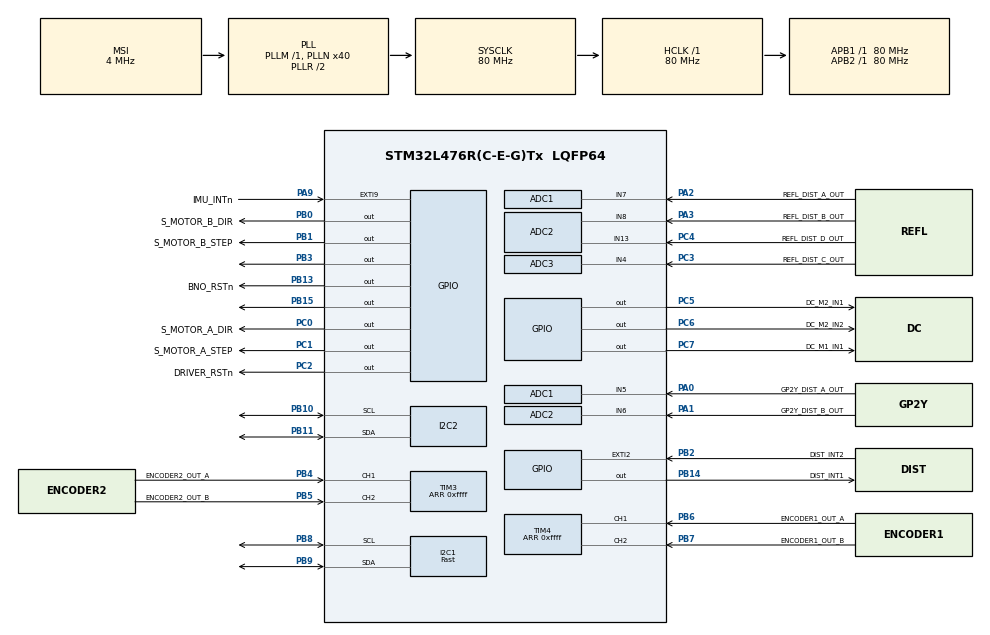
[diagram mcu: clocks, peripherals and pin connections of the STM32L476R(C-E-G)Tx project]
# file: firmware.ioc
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ADC1.Channel-0\#ChannelRegularConversion=ADC_CHANNEL_5
ADC1.Channel-1\#ChannelRegularConversion=ADC_CHANNEL_7
ADC1.ClockPrescaler=ADC_CLOCK_ASYNC_DIV2
ADC1.ContinuousConvMode=ENABLE
ADC1.DMAContinuousRequests=ENABLE
ADC1.DataAlign=ADC_DATAALIGN_RIGHT
ADC1.DiscontinuousConvMode=DISABLE
ADC1.EOCSelection=ADC_EOC_SINGLE_CONV
ADC1.EnableAnalogWatchDog1=false
ADC1.EnableAnalogWatchDog2=false
ADC1.EnableAnalogWatchDog3=false
ADC1.EnableInjectedConversion=DISABLE
ADC1.EnableRegularConversion=ENABLE
ADC1.ExternalTrigConv=ADC_SOFTWARE_START
ADC1.ExternalTrigConvEdge=ADC_EXTERNALTRIGCONVEDGE_NONE
ADC1.LowPowerAutoWait=DISABLE
ADC1.NbrOfConversion=2
ADC1.NbrOfConversionFlag=1
ADC1.OffsetNumber-0\#ChannelRegularConversion=ADC_OFFSET_NONE
ADC1.OffsetNumber-1\#ChannelRegularConversion=ADC_OFFSET_NONE
ADC1.Overrun=ADC_OVR_DATA_OVERWRITTEN
ADC1.OversamplingMode=ENABLE
ADC1.OversamplingStopReset=ADC_REGOVERSAMPLING_CONTINUED_MODE
ADC1.Rank-0\#ChannelRegularConversion=1
ADC1.Rank-1\#ChannelRegularConversion=2
ADC1.Ratio=ADC_OVERSAMPLING_RATIO_256
ADC1.Resolution=ADC_RESOLUTION_12B
ADC1.RightBitShift=ADC_RIGHTBITSHIFT_8
ADC1.SamplingTime-0\#ChannelRegularConversion=ADC_SAMPLETIME_640CYCLES_5
ADC1.SamplingTime-1\#ChannelRegularConversion=ADC_SAMPLETIME_640CYCLES_5
ADC1.ScanConvMode=ADC_SCAN_ENABLE
ADC1.TriggeredMode=ADC_TRIGGEREDMODE_SINGLE_TRIGGER
ADC1.master=1
ADC2.Channel-0\#ChannelRegularConversion=ADC_CHANNEL_6
ADC2.ClockPrescaler=ADC_CLOCK_ASYNC_DIV2
ADC2.ContinuousConvMode=ENABLE
ADC2.DMAContinuousRequests=ENABLE
ADC2.NbrOfConversionFlag=1
ADC2.OffsetNumber-0\#ChannelRegularConversion=ADC_OFFSET_NONE
ADC2.Overrun=ADC_OVR_DATA_OVERWRITTEN
ADC2.OversamplingMode=ENABLE
ADC2.Rank-0\#ChannelRegularConversion=1
ADC2.Ratio=ADC_OVERSAMPLING_RATIO_256
ADC2.RightBitShift=ADC_RIGHTBITSHIFT_8
ADC2.SamplingTime-0\#ChannelRegularConversion=ADC_SAMPLETIME_2CYCLES_5
ADC3.Channel-0\#ChannelRegularConversion=ADC_CHANNEL_4
ADC3.ClockPrescaler=ADC_CLOCK_ASYNC_DIV2
ADC3.ContinuousConvMode=ENABLE
ADC3.DMAContinuousRequests=ENABLE
ADC3.NbrOfConversionFlag=1
ADC3.OffsetNumber-0\#ChannelRegularConversion=ADC_OFFSET_NONE
ADC3.Overrun=ADC_OVR_DATA_OVERWRITTEN
ADC3.OversamplingMode=ENABLE
ADC3.Rank-0\#ChannelRegularConversion=1
ADC3.Ratio=ADC_OVERSAMPLING_RATIO_256
ADC3.RightBitShift=ADC_RIGHTBITSHIFT_8
ADC3.SamplingTime-0\#ChannelRegularConversion=ADC_SAMPLETIME_2CYCLES_5
Dma.ADC1.2.Direction=DMA_PERIPH_TO_MEMORY
Dma.ADC1.2.Instance=DMA1_Channel1
Dma.ADC1.2.MemDataAlignment=DMA_MDATAALIGN_HALFWORD
Dma.ADC1.2.MemInc=DMA_MINC_ENABLE
Dma.ADC1.2.Mode=DMA_CIRCULAR
Dma.ADC1.2.PeriphDataAlignment=DMA_PDATAALIGN_HALFWORD
Dma.ADC1.2.PeriphInc=DMA_PINC_DISABLE
Dma.ADC1.2.Priority=DMA_PRIORITY_LOW
Dma.ADC2.0.Direction=DMA_PERIPH_TO_MEMORY
Dma.ADC2.0.Instance=DMA1_Channel2
Dma.ADC2.0.MemDataAlignment=DMA_MDATAALIGN_HALFWORD
Dma.ADC2.0.MemInc=DMA_MINC_ENABLE
Dma.ADC2.0.Mode=DMA_CIRCULAR
Dma.ADC2.0.PeriphDataAlignment=DMA_PDATAALIGN_HALFWORD
Dma.ADC2.0.PeriphInc=DMA_PINC_DISABLE
Dma.ADC2.0.Priority=DMA_PRIORITY_LOW
Dma.ADC3.1.Direction=DMA_PERIPH_TO_MEMORY
Dma.ADC3.1.Instance=DMA2_Channel5
Dma.ADC3.1.MemDataAlignment=DMA_MDATAALIGN_HALFWORD
Dma.ADC3.1.MemInc=DMA_MINC_ENABLE
Dma.ADC3.1.Mode=DMA_CIRCULAR
Dma.ADC3.1.PeriphDataAlignment=DMA_PDATAALIGN_HALFWORD
Dma.ADC3.1.PeriphInc=DMA_PINC_DISABLE
Dma.ADC3.1.Priority=DMA_PRIORITY_LOW
Dma.Request0=ADC2
Dma.Request1=ADC3
Dma.Request2=ADC1
I2C1.I2C_Fall_Time=200
I2C1.I2C_Rise_Time=200
I2C1.I2C_Speed_Mode=I2C_Fast
I2C1.Speed=400
I2C1.Timing=0x10B51438
I2C2.Timing=0x10909CEC
Mcu.Family=STM32L4
Mcu.Name=STM32L476R(C-E-G)Tx
Mcu.Package=LQFP64
NVIC.DMA1_Channel1_IRQn=true\:0\:0\:false\:false\:true
NVIC.DMA1_Channel2_IRQn=true\:0\:0\:false\:false\:true
NVIC.DMA2_Channel5_IRQn=true\:0\:0\:false\:false\:true
NVIC.PriorityGroup=NVIC_PRIORITYGROUP_4
NVIC.TIM1_UP_TIM16_IRQn=true\:0\:0\:false\:true\:true\:1
NVIC.TIM2_IRQn=true\:0\:0\:false\:true\:true\:2
PA0.GPIO_Label=GP2Y_DIST_A_OUT
PA0.Signal=ADCx_IN5
PA1.GPIO_Label=GP2Y_DIST_B_OUT
PA1.Signal=ADCx_IN6
PA13.GPIO_Label=SWDIO
PA13.Mode=Serial_Wire
PA13.Signal=SYS_JTMS-SWDIO
PA14.GPIO_Label=SWCLK
PA14.Mode=Serial_Wire
PA14.Signal=SYS_JTCK-SWCLK
PA2.GPIO_Label=REFL_DIST_A_OUT
PA2.Signal=ADCx_IN7
PA3.GPIO_Label=REFL_DIST_B_OUT
PA3.Signal=ADCx_IN8
PA9.GPIO_Label=IMU_INTn
PA9.Signal=GPXTI9
PB0.GPIO_Label=S_MOTOR_B_DIR
PB0.Signal=GPIO_Output
PB1.GPIO_Label=S_MOTOR_B_STEP
PB1.Signal=GPIO_Output
PB10.Mode=I2C
PB10.Signal=I2C2_SCL
PB11.Mode=I2C
PB11.Signal=I2C2_SDA
PB13.GPIO_Label=BNO_RSTn
PB13.Signal=GPIO_Output
PB14.GPIO_Label=DIST_INT1
PB14.Signal=GPIO_Output
PB15.Signal=GPIO_Output
PB2.GPIO_Label=DIST_INT2
PB2.Signal=GPXTI2
PB3.Signal=GPIO_Output
PB4.GPIO_Label=ENCODER2_OUT_A
PB4.Signal=S_TIM3_CH1
PB5.GPIO_Label=ENCODER2_OUT_B
PB5.Signal=S_TIM3_CH2
PB6.GPIO_Label=ENCODER1_OUT_A
PB6.Signal=S_TIM4_CH1
PB7.GPIO_Label=ENCODER1_OUT_B
PB7.Signal=S_TIM4_CH2
PB8.Mode=I2C
PB8.Signal=I2C1_SCL
PB9.Mode=I2C
PB9.Signal=I2C1_SDA
PC0.GPIO_Label=S_MOTOR_A_DIR
PC0.Signal=GPIO_Output
PC1.GPIO_Label=S_MOTOR_A_STEP
PC1.Signal=GPIO_Output
PC14/OSC32_IN.GPIO_Label=OSC32_IN
PC14/OSC32_IN.Mode=LSE-External-Oscillator
PC14/OSC32_IN.Signal=RCC_OSC32_IN
PC15/OSC32_OUT.GPIO_Label=OSC32_OUT
PC15/OSC32_OUT.Mode=LSE-External-Oscillator
PC15/OSC32_OUT.Signal=RCC_OSC32_OUT
PC2.GPIO_Label=DRIVER_RSTn
PC2.Signal=GPIO_Output
PC3.GPIO_Label=REFL_DIST_C_OUT
PC3.Signal=ADCx_IN4
PC4.GPIO_Label=REFL_DIST_D_OUT
PC4.Signal=ADCx_IN13
PC5.GPIO_Label=DC_M2_IN1
PC5.Signal=GPIO_Output
PC6.GPIO_Label=DC_M2_IN2
PC6.Signal=GPIO_Output
PC7.GPIO_Label=DC_M1_IN1
PC7.Signal=GPIO_Output
ProjectManager.HeapSize=0x200
ProjectManager.StackSize=0x400
ProjectManager.TargetToolchain=Other Toolchains (GPDSC)
RCC.ADCCLockSelection=RCC_ADCCLKSOURCE_SYSCLK
RCC.ADCFreq_Value=80000000
RCC.AHBFreq_Value=80000000
RCC.APB1Freq_Value=80000000
RCC.APB1TimFreq_Value=80000000
RCC.APB2Freq_Value=80000000
RCC.APB2TimFreq_Value=80000000
RCC.CortexFreq_Value=80000000
RCC.HCLKFreq_Value=80000000
RCC.HSE_VALUE=8000000
RCC.HSI_VALUE=16000000
RCC.MSI_VALUE=4000000
RCC.PLLN=10
RCC.PLLQ=RCC_PLLQ_DIV4
RCC.PLLSAI1R=RCC_PLLR_DIV4
RCC.PLLSourceVirtual=RCC_PLLSOURCE_HSI
RCC.PWR_Regulator_Voltage_Scale=PWR_REGULATOR_VOLTAGE_SCALE1
RCC.SYSCLKFreq_VALUE=80000000
RCC.SYSCLKSource=RCC_SYSCLKSOURCE_PLLCLK
RCC.USBFreq_Value=64000000
RCC.VCOOutputFreq_Value=160000000
SH.ADCx_IN13.0=ADC2_IN13,IN13-Single-Ended
SH.ADCx_IN4.0=ADC3_IN4,IN4-Single-Ended
SH.ADCx_IN5.0=ADC1_IN5,IN5-Single-Ended
SH.ADCx_IN6.0=ADC2_IN6,IN6-Single-Ended
SH.ADCx_IN7.0=ADC1_IN7,IN7-Single-Ended
SH.ADCx_IN8.0=ADC2_IN8,IN8-Single-Ended
SH.S_TIM3_CH1.0=TIM3_CH1,Encoder_Interface
SH.S_TIM3_CH2.0=TIM3_CH2,Encoder_Interface
SH.S_TIM4_CH1.0=TIM4_CH1,Encoder_Interface
SH.S_TIM4_CH2.0=TIM4_CH2,Encoder_Interface
TIM1.Period=0
TIM1.Prescaler=1
TIM3.EncoderMode=TIM_ENCODERMODE_TI12
TIM3.Period=0xffff
TIM4.EncoderMode=TIM_ENCODERMODE_TI12
TIM4.Period=0xffff
VP_TIM1_VS_ClockSourceINT.Mode=Internal
VP_TIM2_VS_ClockSourceINT.Mode=Internal
board=firmware

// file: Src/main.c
/**
  ******************************************************************************
  * File Name          : main.c
  * Description        : Main program body
  ******************************************************************************
  *
  * COPYRIGHT(c) 2017 STMicroelectronics
  *
  * Redistribution and use in source and binary forms, with or without modification,
  * are permitted provided that the following conditions are met:
  *   1. Redistributions of source code must retain the above copyright notice,
  *      this list of conditions and the following disclaimer.
  *   2. Redistributions in binary form must reproduce the above copyright notice,
  *      this list of conditions and the following disclaimer in the documentation
  *      and/or other materials provided with the distribution.
  *   3. Neither the name of STMicroelectronics nor the names of its contributors
  *      may be used to endorse or promote products derived from this software
  *      without specific prior written permission.
  *
  * THIS SOFTWARE IS PROVIDED BY THE COPYRIGHT HOLDERS AND CONTRIBUTORS "AS IS"
  * AND ANY EXPRESS OR IMPLIED WARRANTIES, INCLUDING, BUT NOT LIMITED TO, THE
  * IMPLIED WARRANTIES OF MERCHANTABILITY AND FITNESS FOR A PARTICULAR PURPOSE ARE
  * DISCLAIMED. IN NO EVENT SHALL THE COPYRIGHT HOLDER OR CONTRIBUTORS BE LIABLE
  * FOR ANY DIRECT, INDIRECT, INCIDENTAL, SPECIAL, EXEMPLARY, OR CONSEQUENTIAL
  * DAMAGES (INCLUDING, BUT NOT LIMITED TO, PROCUREMENT OF SUBSTITUTE GOODS OR
  * SERVICES; LOSS OF USE, DATA, OR PROFITS; OR BUSINESS INTERRUPTION) HOWEVER
  * CAUSED AND ON ANY THEORY OF LIABILITY, WHETHER IN CONTRACT, STRICT LIABILITY,
  * OR TORT (INCLUDING NEGLIGENCE OR OTHERWISE) ARISING IN ANY WAY OUT OF THE USE
  * OF THIS SOFTWARE, EVEN IF ADVISED OF THE POSSIBILITY OF SUCH DAMAGE.
  *
  ******************************************************************************
  */
#include "main.h"

/* USER CODE BEGIN Includes */
#ifdef __cplusplus
extern "C"
#endif
/* USER CODE END Includes */

ADC_HandleTypeDef hadc1;
ADC_HandleTypeDef hadc2;
ADC_HandleTypeDef hadc3;
DMA_HandleTypeDef hdma_adc1;
DMA_HandleTypeDef hdma_adc2;
DMA_HandleTypeDef hdma_adc3;

I2C_HandleTypeDef hi2c1;
I2C_HandleTypeDef hi2c2;

TIM_HandleTypeDef htim1;
TIM_HandleTypeDef htim2;
TIM_HandleTypeDef htim3;
TIM_HandleTypeDef htim4;

/* USER CODE BEGIN PV */
/* Private variables ---------------------------------------------------------*/

/* USER CODE END PV */

void SystemClock_Config(void);
void Error_Handler(void);
static void MX_GPIO_Init(void);
static void MX_DMA_Init(void);
static void MX_ADC1_Init(void);
static void MX_ADC2_Init(void);
static void MX_ADC3_Init(void);
static void MX_I2C1_Init(void);
static void MX_I2C2_Init(void);
static void MX_TIM3_Init(void);
static void MX_TIM4_Init(void);
static void MX_TIM1_Init(void);
static void MX_TIM2_Init(void);
static void MX_NVIC_Init(void);

/* USER CODE BEGIN PFP */
/* Private function prototypes -----------------------------------------------*/

/* USER CODE END PFP */

int CMain(void)
{

  /* MCU Configuration----------------------------------------------------------*/

  /* Reset of all peripherals, Initializes the Flash interface and the Systick. */
  HAL_Init();

  /* Configure the system clock */
  SystemClock_Config();

  /* Initialize all configured peripherals */
  MX_GPIO_Init();
  MX_DMA_Init();
  MX_ADC1_Init();
  MX_ADC2_Init();
  MX_ADC3_Init();
  MX_I2C1_Init();
  MX_I2C2_Init();
  MX_TIM3_Init();
  MX_TIM4_Init();
  MX_TIM1_Init();
  MX_TIM2_Init();

  /* Initialize interrupts */
  MX_NVIC_Init();

  /* USER CODE BEGIN 2 */
    HAL_NVIC_SetPriority(TIM1_UP_TIM16_IRQn, 0, 0);
    HAL_NVIC_EnableIRQ(TIM1_UP_TIM16_IRQn);
  /* USER CODE END 2 */

  /* Infinite loop */

  /* USER CODE BEGIN 3 */
    return 0;
  /* USER CODE END 3 */

}

/** System Clock Configuration
*/
void SystemClock_Config(void)
{

  RCC_OscInitTypeDef RCC_OscInitStruct;
  RCC_ClkInitTypeDef RCC_ClkInitStruct;
  RCC_PeriphCLKInitTypeDef PeriphClkInit;

    /**Initializes the CPU, AHB and APB busses clocks
    */
  RCC_OscInitStruct.OscillatorType = RCC_OSCILLATORTYPE_LSE|RCC_OSCILLATORTYPE_MSI;
  RCC_OscInitStruct.LSEState = RCC_LSE_ON;
  RCC_OscInitStruct.MSIState = RCC_MSI_ON;
  RCC_OscInitStruct.MSICalibrationValue = 0;
  RCC_OscInitStruct.MSIClockRange = RCC_MSIRANGE_6;
  RCC_OscInitStruct.PLL.PLLState = RCC_PLL_ON;
  RCC_OscInitStruct.PLL.PLLSource = RCC_PLLSOURCE_MSI;
  RCC_OscInitStruct.PLL.PLLM = 1;
  RCC_OscInitStruct.PLL.PLLN = 40;
  RCC_OscInitStruct.PLL.PLLP = RCC_PLLP_DIV7;
  RCC_OscInitStruct.PLL.PLLQ = RCC_PLLQ_DIV4;
  RCC_OscInitStruct.PLL.PLLR = RCC_PLLR_DIV2;
  if (HAL_RCC_OscConfig(&RCC_OscInitStruct) != HAL_OK)
  {
    Error_Handler();
  }

    /**Initializes the CPU, AHB and APB busses clocks
    */
  RCC_ClkInitStruct.ClockType = RCC_CLOCKTYPE_HCLK|RCC_CLOCKTYPE_SYSCLK
                              |RCC_CLOCKTYPE_PCLK1|RCC_CLOCKTYPE_PCLK2;
  RCC_ClkInitStruct.SYSCLKSource = RCC_SYSCLKSOURCE_PLLCLK;
  RCC_ClkInitStruct.AHBCLKDivider = RCC_SYSCLK_DIV1;
  RCC_ClkInitStruct.APB1CLKDivider = RCC_HCLK_DIV1;
  RCC_ClkInitStruct.APB2CLKDivider = RCC_HCLK_DIV1;

  if (HAL_RCC_ClockConfig(&RCC_ClkInitStruct, FLASH_LATENCY_4) != HAL_OK)
  {
    Error_Handler();
  }

  PeriphClkInit.PeriphClockSelection = RCC_PERIPHCLK_I2C1|RCC_PERIPHCLK_I2C2
                              |RCC_PERIPHCLK_ADC;
  PeriphClkInit.I2c1ClockSelection = RCC_I2C1CLKSOURCE_PCLK1;
  PeriphClkInit.I2c2ClockSelection = RCC_I2C2CLKSOURCE_PCLK1;
  PeriphClkInit.AdcClockSelection = RCC_ADCCLKSOURCE_PLLSAI1;
  PeriphClkInit.PLLSAI1.PLLSAI1Source = RCC_PLLSOURCE_MSI;
  PeriphClkInit.PLLSAI1.PLLSAI1M = 1;
  PeriphClkInit.PLLSAI1.PLLSAI1N = 16;
  PeriphClkInit.PLLSAI1.PLLSAI1P = RCC_PLLP_DIV7;
  PeriphClkInit.PLLSAI1.PLLSAI1Q = RCC_PLLQ_DIV2;
  PeriphClkInit.PLLSAI1.PLLSAI1R = RCC_PLLR_DIV2;
  PeriphClkInit.PLLSAI1.PLLSAI1ClockOut = RCC_PLLSAI1_ADC1CLK;
  if (HAL_RCCEx_PeriphCLKConfig(&PeriphClkInit) != HAL_OK)
  {
    Error_Handler();
  }

    /**Configure LSE Drive Capability
    */
  __HAL_RCC_LSEDRIVE_CONFIG(RCC_LSEDRIVE_LOW);

    /**Configure the main internal regulator output voltage
    */
  if (HAL_PWREx_ControlVoltageScaling(PWR_REGULATOR_VOLTAGE_SCALE1) != HAL_OK)
  {
    Error_Handler();
  }

    /**Configure the Systick interrupt time
    */
  HAL_SYSTICK_Config(HAL_RCC_GetHCLKFreq()/1000);

    /**Configure the Systick
    */
  HAL_SYSTICK_CLKSourceConfig(SYSTICK_CLKSOURCE_HCLK);

    /**Enable MSI Auto calibration
    */
  HAL_RCCEx_EnableMSIPLLMode();

  /* SysTick_IRQn interrupt configuration */
  HAL_NVIC_SetPriority(SysTick_IRQn, 0, 0);
}

/** NVIC Configuration
*/
static void MX_NVIC_Init(void)
{
  /* TIM1_UP_TIM16_IRQn interrupt configuration */
  HAL_NVIC_SetPriority(TIM1_UP_TIM16_IRQn, 0, 0);
  HAL_NVIC_EnableIRQ(TIM1_UP_TIM16_IRQn);
  /* TIM2_IRQn interrupt configuration */
  HAL_NVIC_SetPriority(TIM2_IRQn, 0, 0);
  HAL_NVIC_EnableIRQ(TIM2_IRQn);
}

/* ADC1 init function */
static void MX_ADC1_Init(void)
{

  ADC_MultiModeTypeDef multimode;
  ADC_ChannelConfTypeDef sConfig;

    /**Common config
    */
  hadc1.Instance = ADC1;
  hadc1.Init.ClockPrescaler = ADC_CLOCK_ASYNC_DIV1;
  hadc1.Init.Resolution = ADC_RESOLUTION_12B;
  hadc1.Init.DataAlign = ADC_DATAALIGN_RIGHT;
  hadc1.Init.ScanConvMode = ADC_SCAN_DISABLE;
  hadc1.Init.EOCSelection = ADC_EOC_SINGLE_CONV;
  hadc1.Init.LowPowerAutoWait = DISABLE;
  hadc1.Init.ContinuousConvMode = ENABLE;
  hadc1.Init.NbrOfConversion = 1;
  hadc1.Init.DiscontinuousConvMode = DISABLE;
  hadc1.Init.NbrOfDiscConversion = 1;
  hadc1.Init.ExternalTrigConv = ADC_SOFTWARE_START;
  hadc1.Init.ExternalTrigConvEdge = ADC_EXTERNALTRIGCONVEDGE_NONE;
  hadc1.Init.DMAContinuousRequests = ENABLE;
  hadc1.Init.Overrun = ADC_OVR_DATA_OVERWRITTEN;
  hadc1.Init.OversamplingMode = ENABLE;
  hadc1.Init.Oversampling.Ratio = ADC_OVERSAMPLING_RATIO_256;
  hadc1.Init.Oversampling.RightBitShift = ADC_RIGHTBITSHIFT_8;
  hadc1.Init.Oversampling.TriggeredMode = ADC_TRIGGEREDMODE_SINGLE_TRIGGER;
  hadc1.Init.Oversampling.OversamplingStopReset = ADC_REGOVERSAMPLING_CONTINUED_MODE;
  if (HAL_ADC_Init(&hadc1) != HAL_OK)
  {
    Error_Handler();
  }

    /**Configure the ADC multi-mode
    */
  multimode.Mode = ADC_MODE_INDEPENDENT;
  if (HAL_ADCEx_MultiModeConfigChannel(&hadc1, &multimode) != HAL_OK)
  {
    Error_Handler();
  }

    /**Configure Regular Channel
    */
  sConfig.Channel = ADC_CHANNEL_5;
  sConfig.Rank = 1;
  sConfig.SamplingTime = ADC_SAMPLETIME_2CYCLES_5;
  sConfig.SingleDiff = ADC_SINGLE_ENDED;
  sConfig.OffsetNumber = ADC_OFFSET_NONE;
  sConfig.Offset = 0;
  if (HAL_ADC_ConfigChannel(&hadc1, &sConfig) != HAL_OK)
  {
    Error_Handler();
  }

}

/* ADC2 init function */
static void MX_ADC2_Init(void)
{

  ADC_ChannelConfTypeDef sConfig;

    /**Common config
    */
  hadc2.Instance = ADC2;
  hadc2.Init.ClockPrescaler = ADC_CLOCK_ASYNC_DIV1;
  hadc2.Init.Resolution = ADC_RESOLUTION_12B;
  hadc2.Init.DataAlign = ADC_DATAALIGN_RIGHT;
  hadc2.Init.ScanConvMode = ADC_SCAN_DISABLE;
  hadc2.Init.EOCSelection = ADC_EOC_SINGLE_CONV;
  hadc2.Init.LowPowerAutoWait = DISABLE;
  hadc2.Init.ContinuousConvMode = ENABLE;
  hadc2.Init.NbrOfConversion = 1;
  hadc2.Init.DiscontinuousConvMode = DISABLE;
  hadc2.Init.NbrOfDiscConversion = 1;
  hadc2.Init.ExternalTrigConv = ADC_SOFTWARE_START;
  hadc2.Init.ExternalTrigConvEdge = ADC_EXTERNALTRIGCONVEDGE_NONE;
  hadc2.Init.DMAContinuousRequests = ENABLE;
  hadc2.Init.Overrun = ADC_OVR_DATA_OVERWRITTEN;
  hadc2.Init.OversamplingMode = ENABLE;
  hadc2.Init.Oversampling.Ratio = ADC_OVERSAMPLING_RATIO_256;
  hadc2.Init.Oversampling.RightBitShift = ADC_RIGHTBITSHIFT_8;
  hadc2.Init.Oversampling.TriggeredMode = ADC_TRIGGEREDMODE_SINGLE_TRIGGER;
  hadc2.Init.Oversampling.OversamplingStopReset = ADC_REGOVERSAMPLING_CONTINUED_MODE;
  if (HAL_ADC_Init(&hadc2) != HAL_OK)
  {
    Error_Handler();
  }

    /**Configure Regular Channel
    */
  sConfig.Channel = ADC_CHANNEL_6;
  sConfig.Rank = 1;
  sConfig.SamplingTime = ADC_SAMPLETIME_2CYCLES_5;
  sConfig.SingleDiff = ADC_SINGLE_ENDED;
  sConfig.OffsetNumber = ADC_OFFSET_NONE;
  sConfig.Offset = 0;
  if (HAL_ADC_ConfigChannel(&hadc2, &sConfig) != HAL_OK)
  {
    Error_Handler();
  }

}

/* ADC3 init function */
static void MX_ADC3_Init(void)
{

  ADC_ChannelConfTypeDef sConfig;

    /**Common config
    */
  hadc3.Instance = ADC3;
  hadc3.Init.ClockPrescaler = ADC_CLOCK_ASYNC_DIV1;
  hadc3.Init.Resolution = ADC_RESOLUTION_12B;
  hadc3.Init.DataAlign = ADC_DATAALIGN_RIGHT;
  hadc3.Init.ScanConvMode = ADC_SCAN_DISABLE;
  hadc3.Init.EOCSelection = ADC_EOC_SINGLE_CONV;
  hadc3.Init.LowPowerAutoWait = DISABLE;
  hadc3.Init.ContinuousConvMode = ENABLE;
  hadc3.Init.NbrOfConversion = 1;
  hadc3.Init.DiscontinuousConvMode = DISABLE;
  hadc3.Init.NbrOfDiscConversion = 1;
  hadc3.Init.ExternalTrigConv = ADC_SOFTWARE_START;
  hadc3.Init.ExternalTrigConvEdge = ADC_EXTERNALTRIGCONVEDGE_NONE;
  hadc3.Init.DMAContinuousRequests = ENABLE;
  hadc3.Init.Overrun = ADC_OVR_DATA_OVERWRITTEN;
  hadc3.Init.OversamplingMode = ENABLE;
  hadc3.Init.Oversampling.Ratio = ADC_OVERSAMPLING_RATIO_256;
  hadc3.Init.Oversampling.RightBitShift = ADC_RIGHTBITSHIFT_8;
  hadc3.Init.Oversampling.TriggeredMode = ADC_TRIGGEREDMODE_SINGLE_TRIGGER;
  hadc3.Init.Oversampling.OversamplingStopReset = ADC_REGOVERSAMPLING_CONTINUED_MODE;
  if (HAL_ADC_Init(&hadc3) != HAL_OK)
  {
    Error_Handler();
  }

    /**Configure Regular Channel
    */
  sConfig.Channel = ADC_CHANNEL_4;
  sConfig.Rank = 1;
  sConfig.SamplingTime = ADC_SAMPLETIME_2CYCLES_5;
  sConfig.SingleDiff = ADC_SINGLE_ENDED;
  sConfig.OffsetNumber = ADC_OFFSET_NONE;
  sConfig.Offset = 0;
  if (HAL_ADC_ConfigChannel(&hadc3, &sConfig) != HAL_OK)
  {
    Error_Handler();
  }

}

/* I2C1 init function */
static void MX_I2C1_Init(void)
{

  hi2c1.Instance = I2C1;
  hi2c1.Init.Timing = 0x10909CEC;
  hi2c1.Init.OwnAddress1 = 0;
  hi2c1.Init.AddressingMode = I2C_ADDRESSINGMODE_7BIT;
  hi2c1.Init.DualAddressMode = I2C_DUALADDRESS_DISABLE;
  hi2c1.Init.OwnAddress2 = 0;
  hi2c1.Init.OwnAddress2Masks = I2C_OA2_NOMASK;
  hi2c1.Init.GeneralCallMode = I2C_GENERALCALL_DISABLE;
  hi2c1.Init.NoStretchMode = I2C_NOSTRETCH_DISABLE;
  if (HAL_I2C_Init(&hi2c1) != HAL_OK)
  {
    Error_Handler();
  }

    /**Configure Analogue filter
    */
  if (HAL_I2CEx_ConfigAnalogFilter(&hi2c1, I2C_ANALOGFILTER_ENABLE) != HAL_OK)
  {
    Error_Handler();
  }

}

/* I2C2 init function */
static void MX_I2C2_Init(void)
{

  hi2c2.Instance = I2C2;
  hi2c2.Init.Timing = 0x10909CEC;
  hi2c2.Init.OwnAddress1 = 0;
  hi2c2.Init.AddressingMode = I2C_ADDRESSINGMODE_7BIT;
  hi2c2.Init.DualAddressMode = I2C_DUALADDRESS_DISABLE;
  hi2c2.Init.OwnAddress2 = 0;
  hi2c2.Init.OwnAddress2Masks = I2C_OA2_NOMASK;
  hi2c2.Init.GeneralCallMode = I2C_GENERALCALL_DISABLE;
  hi2c2.Init.NoStretchMode = I2C_NOSTRETCH_DISABLE;
  if (HAL_I2C_Init(&hi2c2) != HAL_OK)
  {
    Error_Handler();
  }

    /**Configure Analogue filter
    */
  if (HAL_I2CEx_ConfigAnalogFilter(&hi2c2, I2C_ANALOGFILTER_ENABLE) != HAL_OK)
  {
    Error_Handler();
  }

}

/* TIM1 init function */
static void MX_TIM1_Init(void)
{

  TIM_ClockConfigTypeDef sClockSourceConfig;
  TIM_MasterConfigTypeDef sMasterConfig;

  htim1.Instance = TIM1;
  htim1.Init.Prescaler = 1;
  htim1.Init.CounterMode = TIM_COUNTERMODE_UP;
  htim1.Init.Period = 0;
  htim1.Init.ClockDivision = TIM_CLOCKDIVISION_DIV1;
  htim1.Init.RepetitionCounter = 0;
  if (HAL_TIM_Base_Init(&htim1) != HAL_OK)
  {
    Error_Handler();
  }

  sClockSourceConfig.ClockSource = TIM_CLOCKSOURCE_INTERNAL;
  if (HAL_TIM_ConfigClockSource(&htim1, &sClockSourceConfig) != HAL_OK)
  {
    Error_Handler();
  }

  sMasterConfig.MasterOutputTrigger = TIM_TRGO_RESET;
  sMasterConfig.MasterOutputTrigger2 = TIM_TRGO2_RESET;
  sMasterConfig.MasterSlaveMode = TIM_MASTERSLAVEMODE_DISABLE;
  if (HAL_TIMEx_MasterConfigSynchronization(&htim1, &sMasterConfig) != HAL_OK)
  {
    Error_Handler();
  }

}

/* TIM2 init function */
static void MX_TIM2_Init(void)
{

  TIM_ClockConfigTypeDef sClockSourceConfig;
  TIM_MasterConfigTypeDef sMasterConfig;

  htim2.Instance = TIM2;
  htim2.Init.Prescaler = 0;
  htim2.Init.CounterMode = TIM_COUNTERMODE_UP;
  htim2.Init.Period = 0;
  htim2.Init.ClockDivision = TIM_CLOCKDIVISION_DIV1;
  if (HAL_TIM_Base_Init(&htim2) != HAL_OK)
  {
    Error_Handler();
  }

  sClockSourceConfig.ClockSource = TIM_CLOCKSOURCE_INTERNAL;
  if (HAL_TIM_ConfigClockSource(&htim2, &sClockSourceConfig) != HAL_OK)
  {
    Error_Handler();
  }

  sMasterConfig.MasterOutputTrigger = TIM_TRGO_RESET;
  sMasterConfig.MasterSlaveMode = TIM_MASTERSLAVEMODE_DISABLE;
  if (HAL_TIMEx_MasterConfigSynchronization(&htim2, &sMasterConfig) != HAL_OK)
  {
    Error_Handler();
  }

}

/* TIM3 init function */
static void MX_TIM3_Init(void)
{

  TIM_Encoder_InitTypeDef sConfig;
  TIM_MasterConfigTypeDef sMasterConfig;

  htim3.Instance = TIM3;
  htim3.Init.Prescaler = 0;
  htim3.Init.CounterMode = TIM_COUNTERMODE_UP;
  htim3.Init.Period = 0xffff;
  htim3.Init.ClockDivision = TIM_CLOCKDIVISION_DIV1;
  sConfig.EncoderMode = TIM_ENCODERMODE_TI12;
  sConfig.IC1Polarity = TIM_ICPOLARITY_RISING;
  sConfig.IC1Selection = TIM_ICSELECTION_DIRECTTI;
  sConfig.IC1Prescaler = TIM_ICPSC_DIV1;
  sConfig.IC1Filter = 0;
  sConfig.IC2Polarity = TIM_ICPOLARITY_RISING;
  sConfig.IC2Selection = TIM_ICSELECTION_DIRECTTI;
  sConfig.IC2Prescaler = TIM_ICPSC_DIV1;
  sConfig.IC2Filter = 0;
  if (HAL_TIM_Encoder_Init(&htim3, &sConfig) != HAL_OK)
  {
    Error_Handler();
  }

  sMasterConfig.MasterOutputTrigger = TIM_TRGO_RESET;
  sMasterConfig.MasterSlaveMode = TIM_MASTERSLAVEMODE_DISABLE;
  if (HAL_TIMEx_MasterConfigSynchronization(&htim3, &sMasterConfig) != HAL_OK)
  {
    Error_Handler();
  }

}

/* TIM4 init function */
static void MX_TIM4_Init(void)
{

  TIM_Encoder_InitTypeDef sConfig;
  TIM_MasterConfigTypeDef sMasterConfig;

  htim4.Instance = TIM4;
  htim4.Init.Prescaler = 0;
  htim4.Init.CounterMode = TIM_COUNTERMODE_UP;
  htim4.Init.Period = 0xffff;
  htim4.Init.ClockDivision = TIM_CLOCKDIVISION_DIV1;
  sConfig.EncoderMode = TIM_ENCODERMODE_TI12;
  sConfig.IC1Polarity = TIM_ICPOLARITY_RISING;
  sConfig.IC1Selection = TIM_ICSELECTION_DIRECTTI;
  sConfig.IC1Prescaler = TIM_ICPSC_DIV1;
  sConfig.IC1Filter = 0;
  sConfig.IC2Polarity = TIM_ICPOLARITY_RISING;
  sConfig.IC2Selection = TIM_ICSELECTION_DIRECTTI;
  sConfig.IC2Prescaler = TIM_ICPSC_DIV1;
  sConfig.IC2Filter = 0;
  if (HAL_TIM_Encoder_Init(&htim4, &sConfig) != HAL_OK)
  {
    Error_Handler();
  }

  sMasterConfig.MasterOutputTrigger = TIM_TRGO_RESET;
  sMasterConfig.MasterSlaveMode = TIM_MASTERSLAVEMODE_DISABLE;
  if (HAL_TIMEx_MasterConfigSynchronization(&htim4, &sMasterConfig) != HAL_OK)
  {
    Error_Handler();
  }

}

static void MX_DMA_Init(void)
{
  /* DMA controller clock enable */
  __HAL_RCC_DMA1_CLK_ENABLE();
  __HAL_RCC_DMA2_CLK_ENABLE();

  /* DMA interrupt init */
  /* DMA1_Channel1_IRQn interrupt configuration */
  HAL_NVIC_SetPriority(DMA1_Channel1_IRQn, 0, 0);
  HAL_NVIC_EnableIRQ(DMA1_Channel1_IRQn);
  /* DMA1_Channel2_IRQn interrupt configuration */
  HAL_NVIC_SetPriority(DMA1_Channel2_IRQn, 0, 0);
  HAL_NVIC_EnableIRQ(DMA1_Channel2_IRQn);
  /* DMA2_Channel5_IRQn interrupt configuration */
  HAL_NVIC_SetPriority(DMA2_Channel5_IRQn, 0, 0);
  HAL_NVIC_EnableIRQ(DMA2_Channel5_IRQn);

}

/** Configure pins as
        * Analog
        * Input
        * Output
        * EVENT_OUT
        * EXTI
*/
static void MX_GPIO_Init(void)
{

  GPIO_InitTypeDef GPIO_InitStruct;

  /* GPIO Ports Clock Enable */
  __HAL_RCC_GPIOC_CLK_ENABLE();
  __HAL_RCC_GPIOA_CLK_ENABLE();
  __HAL_RCC_GPIOB_CLK_ENABLE();

  /*Configure GPIO pin Output Level */
  HAL_GPIO_WritePin(GPIOC, S_MOTOR_A_DIR_Pin|S_MOTOR_A_STEP_Pin|DRIVER_RSTn_Pin|DC_M2_IN1_Pin
                          |DC_M2_IN2_Pin|DC_M1_IN1_Pin, GPIO_PIN_RESET);

  /*Configure GPIO pin Output Level */
  HAL_GPIO_WritePin(GPIOB, S_MOTOR_B_DIR_Pin|S_MOTOR_B_STEP_Pin|BNO_RSTn_Pin|DIST_INT1_Pin, GPIO_PIN_RESET);

  /*Configure GPIO pins : S_MOTOR_A_DIR_Pin S_MOTOR_A_STEP_Pin DRIVER_RSTn_Pin DC_M2_IN1_Pin
                           DC_M2_IN2_Pin DC_M1_IN1_Pin */
  GPIO_InitStruct.Pin = S_MOTOR_A_DIR_Pin|S_MOTOR_A_STEP_Pin|DRIVER_RSTn_Pin|DC_M2_IN1_Pin
                          |DC_M2_IN2_Pin|DC_M1_IN1_Pin;
  GPIO_InitStruct.Mode = GPIO_MODE_OUTPUT_PP;
  GPIO_InitStruct.Pull = GPIO_NOPULL;
  GPIO_InitStruct.Speed = GPIO_SPEED_FREQ_LOW;
  HAL_GPIO_Init(GPIOC, &GPIO_InitStruct);

  /*Configure GPIO pins : S_MOTOR_B_DIR_Pin S_MOTOR_B_STEP_Pin BNO_RSTn_Pin DIST_INT1_Pin */
  GPIO_InitStruct.Pin = S_MOTOR_B_DIR_Pin|S_MOTOR_B_STEP_Pin|BNO_RSTn_Pin|DIST_INT1_Pin;
  GPIO_InitStruct.Mode = GPIO_MODE_OUTPUT_PP;
  GPIO_InitStruct.Pull = GPIO_NOPULL;
  GPIO_InitStruct.Speed = GPIO_SPEED_FREQ_LOW;
  HAL_GPIO_Init(GPIOB, &GPIO_InitStruct);

  /*Configure GPIO pin : DIST_INT2_Pin */
  GPIO_InitStruct.Pin = DIST_INT2_Pin;
  GPIO_InitStruct.Mode = GPIO_MODE_IT_RISING;
  GPIO_InitStruct.Pull = GPIO_NOPULL;
  HAL_GPIO_Init(DIST_INT2_GPIO_Port, &GPIO_InitStruct);

  /*Configure GPIO pin : SD_CARD_DETECT_Pin */
  GPIO_InitStruct.Pin = SD_CARD_DETECT_Pin;
  GPIO_InitStruct.Mode = GPIO_MODE_INPUT;
  GPIO_InitStruct.Pull = GPIO_NOPULL;
  HAL_GPIO_Init(SD_CARD_DETECT_GPIO_Port, &GPIO_InitStruct);

  /*Configure GPIO pin : IMU_INTn_Pin */
  GPIO_InitStruct.Pin = IMU_INTn_Pin;
  GPIO_InitStruct.Mode = GPIO_MODE_IT_RISING;
  GPIO_InitStruct.Pull = GPIO_NOPULL;
  HAL_GPIO_Init(IMU_INTn_GPIO_Port, &GPIO_InitStruct);

}

/* USER CODE BEGIN 4 */
ADC_HandleTypeDef* getADC1Handle()
{
    return &hadc1;
}

ADC_HandleTypeDef* getADC2Handle()
{
    return &hadc2;
}

ADC_HandleTypeDef* getADC3Handle()
{
    return &hadc3;
}

DMA_HandleTypeDef* getDMAADC1Handle()
{
    return &hdma_adc1;
}

DMA_HandleTypeDef* getDMAADC2Handle()
{
    return &hdma_adc2;
}

DMA_HandleTypeDef* getDMAADC3Handle()
{
    return &hdma_adc3;
}

I2C_HandleTypeDef* getI2C1Handle()
{
    return &hi2c1;
}

I2C_HandleTypeDef* getI2C2Handle()
{
    return &hi2c2;
}

TIM_HandleTypeDef* getTIM1Handle()
{
    return &htim1;
}

TIM_HandleTypeDef* getTIM2Handle()
{
    return &htim2;
}

TIM_HandleTypeDef* getTIM3Handle()
{
    return &htim3;
}

TIM_HandleTypeDef* getTIM4Handle()
{
    return &htim4;
}

/* USER CODE END 4 */

void Error_Handler(void)
{
  while(1)
  {
  }
}

/************************ (C) COPYRIGHT STMicroelectronics *****END OF FILE****/
